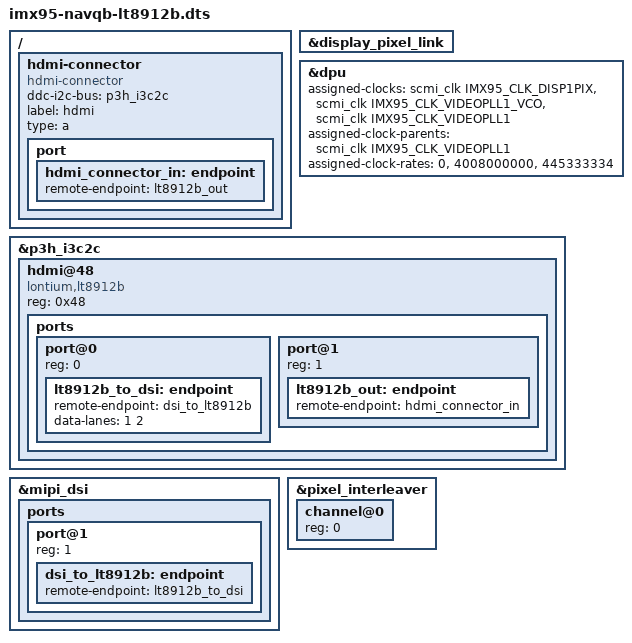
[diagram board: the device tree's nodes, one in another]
// SPDX-License-Identifier: (GPL-2.0+ OR MIT)
/*
 * Copyright 2026 NXP
 */

#include "imx95-navqb.dts"

/ {
	hdmi-connector {
		compatible = "hdmi-connector";
		ddc-i2c-bus = <&p3h_i3c2c>;
		label = "hdmi";
		type = "a";

		port {
			hdmi_connector_in: endpoint {
				remote-endpoint = <&lt8912b_out>;
			};
		};
	};
};

&display_pixel_link {
	status = "okay";
};

&dpu {
	assigned-clocks = <&scmi_clk IMX95_CLK_DISP1PIX>,
			  <&scmi_clk IMX95_CLK_VIDEOPLL1_VCO>,
			  <&scmi_clk IMX95_CLK_VIDEOPLL1>;
	assigned-clock-parents = <&scmi_clk IMX95_CLK_VIDEOPLL1>;
	assigned-clock-rates = <0>, <4008000000>, <445333334>;
};

&p3h_i3c2c {
	#address-cells = <1>;
	#size-cells = <0>;

	hdmi@48 {
		compatible = "lontium,lt8912b";
		reg = <0x48>;
		status = "okay";

		ports {
			#address-cells = <1>;
			#size-cells = <0>;

			port@0 {
				reg = <0>;

				lt8912b_to_dsi: endpoint {
					remote-endpoint = <&dsi_to_lt8912b>;
					data-lanes = <1 2>;
				};
			};

			port@1 {
				reg = <1>;

				lt8912b_out: endpoint {
					remote-endpoint = <&hdmi_connector_in>;
				};
			};
		};
	};
};

&mipi_dsi {
	status = "okay";

	ports {
		#address-cells = <1>;
		#size-cells = <0>;

		port@1 {
			reg = <1>;

			dsi_to_lt8912b: endpoint {
				remote-endpoint = <&lt8912b_to_dsi>;
			};
		};
	};
};

&pixel_interleaver {
	#address-cells = <1>;
	#size-cells = <0>;
	status = "okay";

	channel@0 {
		reg = <0>;
		status = "okay";
	};
};

